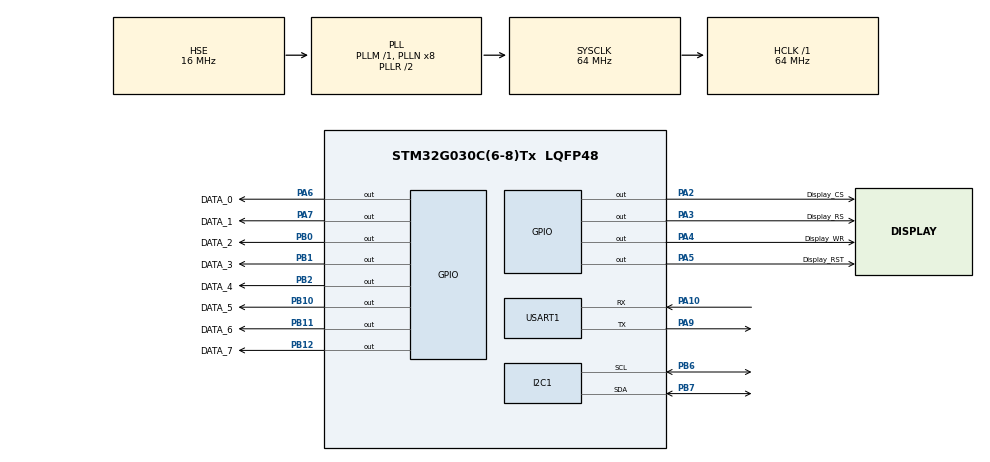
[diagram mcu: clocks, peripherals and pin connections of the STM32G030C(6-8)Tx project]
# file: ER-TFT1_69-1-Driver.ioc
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I2C1.Timing=0x10707DBC
Mcu.Family=STM32G0
Mcu.Name=STM32G030C(6-8)Tx
Mcu.Package=LQFP48
PA10.Mode=Asynchronous
PA10.Signal=USART1_RX
PA13.Mode=Serial_Wire
PA13.Signal=SYS_SWDIO
PA14-BOOT0.Mode=Serial_Wire
PA14-BOOT0.Signal=SYS_SWCLK
PA2.GPIO_Label=Display_CS
PA2.GPIO_Speed=GPIO_SPEED_FREQ_VERY_HIGH
PA2.Signal=GPIO_Output
PA3.GPIO_Label=Display_RS
PA3.GPIO_Speed=GPIO_SPEED_FREQ_VERY_HIGH
PA3.Signal=GPIO_Output
PA4.GPIO_Label=Display_WR
PA4.GPIO_Speed=GPIO_SPEED_FREQ_VERY_HIGH
PA4.Signal=GPIO_Output
PA5.GPIO_Label=Display_RST
PA5.GPIO_Speed=GPIO_SPEED_FREQ_VERY_HIGH
PA5.PinState=GPIO_PIN_SET
PA5.Signal=GPIO_Output
PA6.GPIO_Label=DATA_0
PA6.GPIO_Speed=GPIO_SPEED_FREQ_VERY_HIGH
PA6.Signal=GPIO_Output
PA7.GPIO_Label=DATA_1
PA7.GPIO_Speed=GPIO_SPEED_FREQ_VERY_HIGH
PA7.Signal=GPIO_Output
PA9.Mode=Asynchronous
PA9.Signal=USART1_TX
PB0.GPIO_Label=DATA_2
PB0.GPIO_Speed=GPIO_SPEED_FREQ_VERY_HIGH
PB0.Signal=GPIO_Output
PB1.GPIO_Label=DATA_3
PB1.GPIO_Speed=GPIO_SPEED_FREQ_VERY_HIGH
PB1.Signal=GPIO_Output
PB10.GPIO_Label=DATA_5
PB10.GPIO_Speed=GPIO_SPEED_FREQ_VERY_HIGH
PB10.Signal=GPIO_Output
PB11.GPIO_Label=DATA_6
PB11.GPIO_Speed=GPIO_SPEED_FREQ_VERY_HIGH
PB11.Signal=GPIO_Output
PB12.GPIO_Label=DATA_7
PB12.GPIO_Speed=GPIO_SPEED_FREQ_VERY_HIGH
PB12.Signal=GPIO_Output
PB2.GPIO_Label=DATA_4
PB2.GPIO_Speed=GPIO_SPEED_FREQ_VERY_HIGH
PB2.Signal=GPIO_Output
PB6.Mode=I2C
PB6.Signal=I2C1_SCL
PB7.Mode=I2C
PB7.Signal=I2C1_SDA
PF0-OSC_IN\ (PF0).Mode=HSE-External-Oscillator
PF0-OSC_IN\ (PF0).Signal=RCC_OSC_IN
PF1-OSC_OUT\ (PF1).Mode=HSE-External-Oscillator
PF1-OSC_OUT\ (PF1).Signal=RCC_OSC_OUT
ProjectManager.HeapSize=0x200
ProjectManager.StackSize=0x400
ProjectManager.TargetToolchain=STM32CubeIDE
RCC.ADCFreq_Value=64000000
RCC.AHBFreq_Value=64000000
RCC.CortexFreq_Value=64000000
RCC.EXTERNAL_CLOCK_VALUE=12288000
RCC.EnbaleCSS=true
RCC.HCLKFreq_Value=64000000
RCC.HSE_VALUE=16000000
RCC.HSI_VALUE=16000000
RCC.LSE_VALUE=32768
RCC.PLLSourceVirtual=RCC_PLLSOURCE_HSE
RCC.SYSCLKFreq_VALUE=64000000
RCC.SYSCLKSource=RCC_SYSCLKSOURCE_PLLCLK
RCC.VCOOutputFreq_Value=128000000
USART1.VirtualMode-Asynchronous=VM_ASYNC
board=custom

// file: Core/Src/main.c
/* USER CODE BEGIN Header */
/**
  ******************************************************************************
  * @file           : main.c
  * @brief          : Main program body
  ******************************************************************************
  * @attention
  *
  * Copyright (c) 2022 STMicroelectronics.
  * All rights reserved.
  *
  * This software is licensed under terms that can be found in the LICENSE file
  * in the root directory of this software component.
  * If no LICENSE file comes with this software, it is provided AS-IS.
  *
  ******************************************************************************
  */
/* USER CODE END Header */
#include "main.h"

/* USER CODE BEGIN Includes */
#include "ST7789V.h"
/* USER CODE END Includes */

I2C_HandleTypeDef hi2c1;

UART_HandleTypeDef huart1;

void SystemClock_Config(void);
static void MX_GPIO_Init(void);
static void MX_I2C1_Init(void);
static void MX_USART1_UART_Init(void);

int main(void)
{

  /* MCU Configuration--------------------------------------------------------*/

  /* Reset of all peripherals, Initializes the Flash interface and the Systick. */
  HAL_Init();

  /* Configure the system clock */
  SystemClock_Config();

  /* Initialize all configured peripherals */
  MX_GPIO_Init();
  MX_I2C1_Init();
  MX_USART1_UART_Init();
  /* USER CODE BEGIN 2 */
  ST7789V_Initial();
  ST7789V_ClearScreen(ST7789V_convert24BitRGBTo16Bit(0x0000FF));
  ST7789V_ShowString(84, 50, "ER-TFT1.69-1", 0x001f, 0x0);
  ST7789V_ShowString(66, 70, "Test Text", 0x00f800, 0xffff);
  ST7789V_ShowString(20, 90, "Some more text", 0x00ffe0, 0x00);

  ST7789V_DrawLine(20, 120, 220, 120, 0x07e0);
  ST7789V_DrawRectangle(40, 140, 200, 180, 0xf81f);
  ST7789V_DrawCircle(120, 120, 115, 0xf800);
  ST7789V_DrawRectangle(0, 0, 239, 279, 0x001F);
  /* USER CODE END 2 */

  /* Infinite loop */
  while (1)
  {

  }
}

void SystemClock_Config(void)
{
  RCC_OscInitTypeDef RCC_OscInitStruct = {0};
  RCC_ClkInitTypeDef RCC_ClkInitStruct = {0};

  /** Configure the main internal regulator output voltage
  */
  HAL_PWREx_ControlVoltageScaling(PWR_REGULATOR_VOLTAGE_SCALE1);
  /** Initializes the RCC Oscillators according to the specified parameters
  * in the RCC_OscInitTypeDef structure.
  */
  RCC_OscInitStruct.OscillatorType = RCC_OSCILLATORTYPE_HSE;
  RCC_OscInitStruct.HSEState = RCC_HSE_ON;
  RCC_OscInitStruct.PLL.PLLState = RCC_PLL_ON;
  RCC_OscInitStruct.PLL.PLLSource = RCC_PLLSOURCE_HSE;
  RCC_OscInitStruct.PLL.PLLM = RCC_PLLM_DIV1;
  RCC_OscInitStruct.PLL.PLLN = 8;
  RCC_OscInitStruct.PLL.PLLP = RCC_PLLP_DIV2;
  RCC_OscInitStruct.PLL.PLLR = RCC_PLLR_DIV2;
  if (HAL_RCC_OscConfig(&RCC_OscInitStruct) != HAL_OK)
  {
    Error_Handler();
  }
  /** Initializes the CPU, AHB and APB buses clocks
  */
  RCC_ClkInitStruct.ClockType = RCC_CLOCKTYPE_HCLK|RCC_CLOCKTYPE_SYSCLK
                              |RCC_CLOCKTYPE_PCLK1;
  RCC_ClkInitStruct.SYSCLKSource = RCC_SYSCLKSOURCE_PLLCLK;
  RCC_ClkInitStruct.AHBCLKDivider = RCC_SYSCLK_DIV1;
  RCC_ClkInitStruct.APB1CLKDivider = RCC_HCLK_DIV1;

  if (HAL_RCC_ClockConfig(&RCC_ClkInitStruct, FLASH_LATENCY_2) != HAL_OK)
  {
    Error_Handler();
  }
  /** Enables the Clock Security System
  */
  HAL_RCC_EnableCSS();
}

static void MX_I2C1_Init(void)
{

  hi2c1.Instance = I2C1;
  hi2c1.Init.Timing = 0x10707DBC;
  hi2c1.Init.OwnAddress1 = 0;
  hi2c1.Init.AddressingMode = I2C_ADDRESSINGMODE_7BIT;
  hi2c1.Init.DualAddressMode = I2C_DUALADDRESS_DISABLE;
  hi2c1.Init.OwnAddress2 = 0;
  hi2c1.Init.OwnAddress2Masks = I2C_OA2_NOMASK;
  hi2c1.Init.GeneralCallMode = I2C_GENERALCALL_DISABLE;
  hi2c1.Init.NoStretchMode = I2C_NOSTRETCH_DISABLE;
  if (HAL_I2C_Init(&hi2c1) != HAL_OK)
  {
    Error_Handler();
  }
  /** Configure Analogue filter
  */
  if (HAL_I2CEx_ConfigAnalogFilter(&hi2c1, I2C_ANALOGFILTER_ENABLE) != HAL_OK)
  {
    Error_Handler();
  }
  /** Configure Digital filter
  */
  if (HAL_I2CEx_ConfigDigitalFilter(&hi2c1, 0) != HAL_OK)
  {
    Error_Handler();
  }

}

static void MX_USART1_UART_Init(void)
{

  huart1.Instance = USART1;
  huart1.Init.BaudRate = 115200;
  huart1.Init.WordLength = UART_WORDLENGTH_8B;
  huart1.Init.StopBits = UART_STOPBITS_1;
  huart1.Init.Parity = UART_PARITY_NONE;
  huart1.Init.Mode = UART_MODE_TX_RX;
  huart1.Init.HwFlowCtl = UART_HWCONTROL_NONE;
  huart1.Init.OverSampling = UART_OVERSAMPLING_16;
  huart1.Init.OneBitSampling = UART_ONE_BIT_SAMPLE_DISABLE;
  huart1.Init.ClockPrescaler = UART_PRESCALER_DIV1;
  huart1.AdvancedInit.AdvFeatureInit = UART_ADVFEATURE_NO_INIT;
  if (HAL_UART_Init(&huart1) != HAL_OK)
  {
    Error_Handler();
  }
  if (HAL_UARTEx_SetTxFifoThreshold(&huart1, UART_TXFIFO_THRESHOLD_1_8) != HAL_OK)
  {
    Error_Handler();
  }
  if (HAL_UARTEx_SetRxFifoThreshold(&huart1, UART_RXFIFO_THRESHOLD_1_8) != HAL_OK)
  {
    Error_Handler();
  }
  if (HAL_UARTEx_DisableFifoMode(&huart1) != HAL_OK)
  {
    Error_Handler();
  }

}

static void MX_GPIO_Init(void)
{
  GPIO_InitTypeDef GPIO_InitStruct = {0};

  /* GPIO Ports Clock Enable */
  __HAL_RCC_GPIOF_CLK_ENABLE();
  __HAL_RCC_GPIOA_CLK_ENABLE();
  __HAL_RCC_GPIOB_CLK_ENABLE();

  /*Configure GPIO pin Output Level */
  HAL_GPIO_WritePin(GPIOA, Display_CS_Pin|Display_RS_Pin|Display_WR_Pin|DATA_0_Pin
                          |DATA_1_Pin, GPIO_PIN_RESET);

  /*Configure GPIO pin Output Level */
  HAL_GPIO_WritePin(Display_RST_GPIO_Port, Display_RST_Pin, GPIO_PIN_SET);

  /*Configure GPIO pin Output Level */
  HAL_GPIO_WritePin(GPIOB, DATA_2_Pin|DATA_3_Pin|DATA_4_Pin|DATA_5_Pin
                          |DATA_6_Pin|DATA_7_Pin, GPIO_PIN_RESET);

  /*Configure GPIO pins : Display_CS_Pin Display_RS_Pin Display_WR_Pin Display_RST_Pin
                           DATA_0_Pin DATA_1_Pin */
  GPIO_InitStruct.Pin = Display_CS_Pin|Display_RS_Pin|Display_WR_Pin|Display_RST_Pin
                          |DATA_0_Pin|DATA_1_Pin;
  GPIO_InitStruct.Mode = GPIO_MODE_OUTPUT_PP;
  GPIO_InitStruct.Pull = GPIO_NOPULL;
  GPIO_InitStruct.Speed = GPIO_SPEED_FREQ_VERY_HIGH;
  HAL_GPIO_Init(GPIOA, &GPIO_InitStruct);

  /*Configure GPIO pins : DATA_2_Pin DATA_3_Pin DATA_4_Pin DATA_5_Pin
                           DATA_6_Pin DATA_7_Pin */
  GPIO_InitStruct.Pin = DATA_2_Pin|DATA_3_Pin|DATA_4_Pin|DATA_5_Pin
                          |DATA_6_Pin|DATA_7_Pin;
  GPIO_InitStruct.Mode = GPIO_MODE_OUTPUT_PP;
  GPIO_InitStruct.Pull = GPIO_NOPULL;
  GPIO_InitStruct.Speed = GPIO_SPEED_FREQ_VERY_HIGH;
  HAL_GPIO_Init(GPIOB, &GPIO_InitStruct);

}

void Error_Handler(void)
{
  __disable_irq();
  while (1)
  {
  }
}
